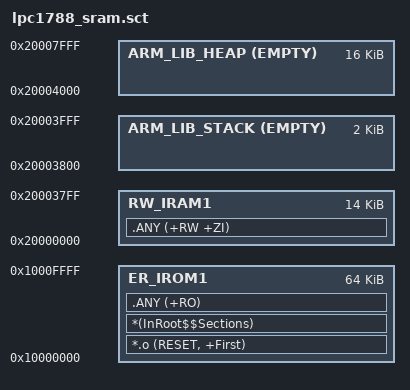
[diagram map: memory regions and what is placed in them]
;*****************************************************************
;* LPC1788 linker scatter file (running code from internal SRAM) *
;*****************************************************************

LR_IRAM1 0x10000000 0x10000
{
   ER_IROM1 0x10000000 0x10000
   {
      *.o (RESET, +First)
      *(InRoot$$Sections)
      .ANY (+RO)
   }
   
   RW_IRAM1 0x20000000 0x3800
   {
      .ANY (+RW +ZI)
   }
   
   ARM_LIB_STACK 0x20004000 EMPTY -0x800
   {
   }
   
   ARM_LIB_HEAP 0x20004000 EMPTY 0x4000
   {
   }
}
